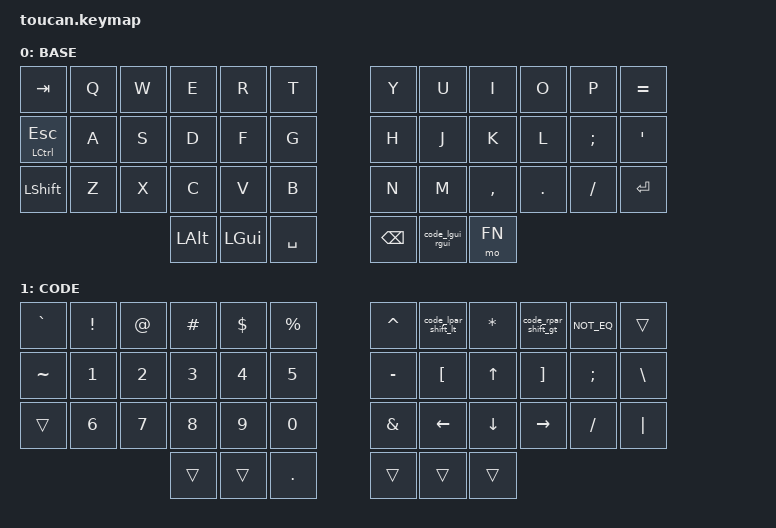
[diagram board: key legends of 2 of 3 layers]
#include <behaviors.dtsi>
#include <dt-bindings/zmk/keys.h>
#include <dt-bindings/zmk/pointing.h>
#include <dt-bindings/zmk/bt.h>

#define BASE 0
#define CODE  1
#define FN  2

/ {
    conditional_layers {
        compatible = "zmk";
    };

    macros {
        NOT_EQ: NOT_EQ {
            compatible = "zmk,behavior-macro";
            #binding-cells = <0>;
            bindings = <&kp EXCL &kp EQUAL>;
            label = "NOT_EQ";
        };
    };

    behaviors {
        bt_clr_hold2s: bt_clr_hold2s {
            compatible = "zmk,behavior-hold-tap";
            label = "BT_CLR_HOLD2S";
            /* Pass through args to hold binding (BT_* is 2 cells) */
            #binding-cells = <2>;
            flavor = "tap-preferred";
            tapping-term-ms = <2000>;
            hold-trigger-on-release;
            bindings = <&bt &trans>;
        };

        code_lpar_shift_lt: code_lpar_shift_lt {
            compatible = "zmk,behavior-mod-morph";
            label = "CODE_LPAR_SHIFT_LT";
            #binding-cells = <0>;
            mods = <(MOD_LSFT | MOD_RSFT)>;
            /* When shift is held, output '<' */
            bindings = <&kp LPAR>, <&kp LT>;
        };

        code_rpar_shift_gt: code_rpar_shift_gt {
            compatible = "zmk,behavior-mod-morph";
            label = "CODE_RPAR_SHIFT_GT";
            #binding-cells = <0>;
            mods = <(MOD_LSFT | MOD_RSFT)>;
            /* When shift is held, output '>' */
            bindings = <&kp RPAR>, <&kp GT>;
        };

        code_rgui_if_alone: code_rgui_if_alone {
            compatible = "zmk,behavior-hold-tap";
            label = "CODE_RGUI_IF_ALONE";
            #binding-cells = <2>;
            flavor = "hold-preferred";
            tapping-term-ms = <200>;
            retro-tap;
            bindings = <&mo>, <&kp>;
        };

        code_lgui_rgui: code_lgui_rgui {
            compatible = "zmk,behavior-mod-morph";
            label = "CODE_LGUI_RGUI";
            #binding-cells = <0>;
            mods = <MOD_LGUI>;
            keep-mods = <MOD_LGUI>;
            bindings = <&mo CODE>, <&code_rgui_if_alone CODE RGUI>;
        };
    };

    keymap {
        compatible = "zmk,keymap";

        base {
            display-name = "BASE";
            bindings = <
                &kp TAB        &kp Q  &kp W  &kp E  &kp R  &kp T       &kp Y  &kp U  &kp I      &kp O    &kp P     &kp EQUAL
                &mt LCTRL ESC  &kp A  &kp S  &kp D  &kp F  &kp G       &kp H  &kp J  &kp K      &kp L    &kp SEMI  &kp SQT
                &kp LSHFT      &kp Z  &kp X  &kp C  &kp V  &kp B       &kp N  &kp M  &kp COMMA  &kp DOT  &kp FSLH  &kp ENTER
                                    &kp LALT &kp LGUI  &kp SPACE       &kp BSPC &code_lgui_rgui &mo FN
            >;
        };

        code {
            display-name = "CODE";
            bindings = <
                &kp GRAVE &kp EXCL &kp AT &kp HASH &kp DLLR &kp PRCNT       &kp CARET &code_lpar_shift_lt &kp STAR  &code_rpar_shift_gt  &NOT_EQ    &trans
                &kp TILDE &kp N1   &kp N2 &kp N3   &kp N4   &kp N5          &kp MINUS &kp LBKT &kp UP    &kp RBKT  &kp SEMI   &kp BSLH
                &trans    &kp N6   &kp N7 &kp N8   &kp N9   &kp N0          &kp AMPS  &kp LEFT &kp DOWN  &kp RIGHT &kp SLASH  &kp PIPE
                                          &trans   &trans   &kp DOT         &trans    &trans   &trans
            >;
        };

        fn {
            display-name = "fn";
            bindings = <
                &kp F1  &kp F2  &kp F3  &kp F4  &kp F5         &kp F6        &kp F7        &kp F8    &kp F9      &kp F10   &kp F11  &kp F12
                &trans  &trans  &trans  &trans  &trans         &kp C_BRI_UP  &kp C_VOL_UP  &trans    &kp PG_UP   &trans    &trans   &trans
        &studio_unlock  &trans  &trans  &trans  &trans         &kp C_BRI_DN  &kp C_VOL_DN  &mkp MB4  &kp PG_DN   &mkp MB5  &trans   &trans
                          &bt BT_PRV &bt BT_NXT &bt_clr_hold2s BT_CLR &kp C_MUTE &trans
            >;
        };
    };
};
